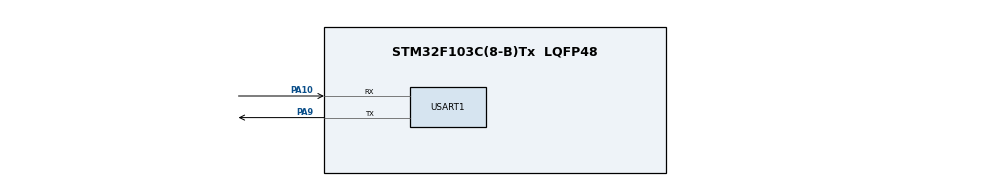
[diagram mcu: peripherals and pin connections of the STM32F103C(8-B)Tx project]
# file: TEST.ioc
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Dma.Request0=USART1_RX
Dma.Request1=USART1_TX
Dma.USART1_RX.0.Direction=DMA_PERIPH_TO_MEMORY
Dma.USART1_RX.0.Instance=DMA1_Channel5
Dma.USART1_RX.0.MemDataAlignment=DMA_MDATAALIGN_BYTE
Dma.USART1_RX.0.MemInc=DMA_MINC_ENABLE
Dma.USART1_RX.0.Mode=DMA_CIRCULAR
Dma.USART1_RX.0.PeriphDataAlignment=DMA_PDATAALIGN_BYTE
Dma.USART1_RX.0.PeriphInc=DMA_PINC_DISABLE
Dma.USART1_RX.0.Priority=DMA_PRIORITY_LOW
Dma.USART1_TX.1.Direction=DMA_MEMORY_TO_PERIPH
Dma.USART1_TX.1.Instance=DMA1_Channel4
Dma.USART1_TX.1.MemDataAlignment=DMA_MDATAALIGN_BYTE
Dma.USART1_TX.1.MemInc=DMA_MINC_ENABLE
Dma.USART1_TX.1.Mode=DMA_NORMAL
Dma.USART1_TX.1.PeriphDataAlignment=DMA_PDATAALIGN_BYTE
Dma.USART1_TX.1.PeriphInc=DMA_PINC_DISABLE
Dma.USART1_TX.1.Priority=DMA_PRIORITY_LOW
Mcu.Family=STM32F1
Mcu.Name=STM32F103C(8-B)Tx
Mcu.Package=LQFP48
NVIC.DMA1_Channel4_IRQn=true\:0\:0\:false\:false\:true\:false\:true
NVIC.DMA1_Channel5_IRQn=true\:0\:0\:false\:false\:true\:false\:true
NVIC.PriorityGroup=NVIC_PRIORITYGROUP_4
NVIC.USART1_IRQn=true\:0\:0\:false\:false\:true\:true\:true
PA10.Mode=Asynchronous
PA10.Signal=USART1_RX
PA13.Mode=Serial_Wire
PA13.Signal=SYS_JTMS-SWDIO
PA14.Mode=Serial_Wire
PA14.Signal=SYS_JTCK-SWCLK
PA9.Mode=Asynchronous
PA9.Signal=USART1_TX
PD0-OSC_IN.Mode=HSE-External-Oscillator
PD0-OSC_IN.Signal=RCC_OSC_IN
PD1-OSC_OUT.Mode=HSE-External-Oscillator
PD1-OSC_OUT.Signal=RCC_OSC_OUT
ProjectManager.HeapSize=0x200
ProjectManager.StackSize=0x400
ProjectManager.TargetToolchain=MDK-ARM V5.27
RCC.AHBFreq_Value=72000000
RCC.APB1CLKDivider=RCC_HCLK_DIV2
RCC.APB1Freq_Value=36000000
RCC.APB1TimFreq_Value=72000000
RCC.APB2Freq_Value=72000000
RCC.APB2TimFreq_Value=72000000
RCC.HCLKFreq_Value=72000000
RCC.PLLMUL=RCC_PLL_MUL9
RCC.PLLSourceVirtual=RCC_PLLSOURCE_HSE
RCC.SYSCLKFreq_VALUE=72000000
RCC.SYSCLKSource=RCC_SYSCLKSOURCE_PLLCLK
RCC.USBFreq_Value=72000000
USART1.VirtualMode=VM_ASYNC
board=custom

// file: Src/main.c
/* USER CODE BEGIN Header */
/**
  ******************************************************************************
  * @file           : main.c
  * @brief          : Main program body
  ******************************************************************************
  * @attention
  *
  * <h2><center>&copy; Copyright (c) 2021 STMicroelectronics.
  * All rights reserved.</center></h2>
  *
  * This software component is licensed by ST under BSD 3-Clause license,
  * the "License"; You may not use this file except in compliance with the
  * License. You may obtain a copy of the License at:
  *                        opensource.org/licenses/BSD-3-Clause
  *
  ******************************************************************************
  */
/* USER CODE END Header */
#include "main.h"

/* USER CODE BEGIN Includes */
#include "dma.h"

/* USER CODE END Includes */

void SystemClock_Config(void);
static void MX_GPIO_Init(void);
static void MX_DMA_Init(void);
static void MX_USART1_UART_Init(void);

int main(void)
{

  /* MCU Configuration--------------------------------------------------------*/

  /* Reset of all peripherals, Initializes the Flash interface and the Systick. */

  LL_APB2_GRP1_EnableClock(LL_APB2_GRP1_PERIPH_AFIO);
  LL_APB1_GRP1_EnableClock(LL_APB1_GRP1_PERIPH_PWR);

  NVIC_SetPriorityGrouping(NVIC_PRIORITYGROUP_4);

  /* System interrupt init*/

  /** NOJTAG: JTAG-DP Disabled and SW-DP Enabled
  */
  LL_GPIO_AF_Remap_SWJ_NOJTAG();

  /* Configure the system clock */
  SystemClock_Config();

  /* Initialize all configured peripherals */
  MX_GPIO_Init();
  MX_DMA_Init();
  MX_USART1_UART_Init();
  /* USER CODE BEGIN 2 */
  LL_Init();
  usart_init();
  usart_send_string("USART DMA example: DMA HT & TC + USART IDLE LINE interrupts\r\n");
  /* USER CODE END 2 */

  /* Infinite loop */
  while (1)
  {

  }
}

void SystemClock_Config(void)
{
  LL_FLASH_SetLatency(LL_FLASH_LATENCY_2);
  while(LL_FLASH_GetLatency()!= LL_FLASH_LATENCY_2)
  {
  }
  LL_RCC_HSE_Enable();

   /* Wait till HSE is ready */
  while(LL_RCC_HSE_IsReady() != 1)
  {

  }
  LL_RCC_PLL_ConfigDomain_SYS(LL_RCC_PLLSOURCE_HSE_DIV_1, LL_RCC_PLL_MUL_9);
  LL_RCC_PLL_Enable();

   /* Wait till PLL is ready */
  while(LL_RCC_PLL_IsReady() != 1)
  {

  }
  LL_RCC_SetAHBPrescaler(LL_RCC_SYSCLK_DIV_1);
  LL_RCC_SetAPB1Prescaler(LL_RCC_APB1_DIV_2);
  LL_RCC_SetAPB2Prescaler(LL_RCC_APB2_DIV_1);
  LL_RCC_SetSysClkSource(LL_RCC_SYS_CLKSOURCE_PLL);

   /* Wait till System clock is ready */
  while(LL_RCC_GetSysClkSource() != LL_RCC_SYS_CLKSOURCE_STATUS_PLL)
  {

  }
  LL_Init1msTick(72000000);
  LL_SetSystemCoreClock(72000000);
}

static void MX_USART1_UART_Init(void)
{

  LL_USART_InitTypeDef USART_InitStruct = {0};

  LL_GPIO_InitTypeDef GPIO_InitStruct = {0};

  /* Peripheral clock enable */
  LL_APB2_GRP1_EnableClock(LL_APB2_GRP1_PERIPH_USART1);

  LL_APB2_GRP1_EnableClock(LL_APB2_GRP1_PERIPH_GPIOA);
  /**USART1 GPIO Configuration
  PA9   ------> USART1_TX
  PA10   ------> USART1_RX
  */
  GPIO_InitStruct.Pin = LL_GPIO_PIN_9;
  GPIO_InitStruct.Mode = LL_GPIO_MODE_ALTERNATE;
  GPIO_InitStruct.Speed = LL_GPIO_SPEED_FREQ_HIGH;
  GPIO_InitStruct.OutputType = LL_GPIO_OUTPUT_PUSHPULL;
  LL_GPIO_Init(GPIOA, &GPIO_InitStruct);

  GPIO_InitStruct.Pin = LL_GPIO_PIN_10;
  GPIO_InitStruct.Mode = LL_GPIO_MODE_FLOATING;
  LL_GPIO_Init(GPIOA, &GPIO_InitStruct);

  /* USART1 DMA Init */

  /* USART1_RX Init */
  LL_DMA_SetDataTransferDirection(DMA1, LL_DMA_CHANNEL_5, LL_DMA_DIRECTION_PERIPH_TO_MEMORY);

  LL_DMA_SetChannelPriorityLevel(DMA1, LL_DMA_CHANNEL_5, LL_DMA_PRIORITY_LOW);

  LL_DMA_SetMode(DMA1, LL_DMA_CHANNEL_5, LL_DMA_MODE_CIRCULAR);

  LL_DMA_SetPeriphIncMode(DMA1, LL_DMA_CHANNEL_5, LL_DMA_PERIPH_NOINCREMENT);

  LL_DMA_SetMemoryIncMode(DMA1, LL_DMA_CHANNEL_5, LL_DMA_MEMORY_INCREMENT);

  LL_DMA_SetPeriphSize(DMA1, LL_DMA_CHANNEL_5, LL_DMA_PDATAALIGN_BYTE);

  LL_DMA_SetMemorySize(DMA1, LL_DMA_CHANNEL_5, LL_DMA_MDATAALIGN_BYTE);

  /* USART1_TX Init */
  LL_DMA_SetDataTransferDirection(DMA1, LL_DMA_CHANNEL_4, LL_DMA_DIRECTION_MEMORY_TO_PERIPH);

  LL_DMA_SetChannelPriorityLevel(DMA1, LL_DMA_CHANNEL_4, LL_DMA_PRIORITY_LOW);

  LL_DMA_SetMode(DMA1, LL_DMA_CHANNEL_4, LL_DMA_MODE_NORMAL);

  LL_DMA_SetPeriphIncMode(DMA1, LL_DMA_CHANNEL_4, LL_DMA_PERIPH_NOINCREMENT);

  LL_DMA_SetMemoryIncMode(DMA1, LL_DMA_CHANNEL_4, LL_DMA_MEMORY_INCREMENT);

  LL_DMA_SetPeriphSize(DMA1, LL_DMA_CHANNEL_4, LL_DMA_PDATAALIGN_BYTE);

  LL_DMA_SetMemorySize(DMA1, LL_DMA_CHANNEL_4, LL_DMA_MDATAALIGN_BYTE);

  /* USART1 interrupt Init */
  NVIC_SetPriority(USART1_IRQn, NVIC_EncodePriority(NVIC_GetPriorityGrouping(),0, 0));
  NVIC_EnableIRQ(USART1_IRQn);

  USART_InitStruct.BaudRate = 115200;
  USART_InitStruct.DataWidth = LL_USART_DATAWIDTH_8B;
  USART_InitStruct.StopBits = LL_USART_STOPBITS_1;
  USART_InitStruct.Parity = LL_USART_PARITY_NONE;
  USART_InitStruct.TransferDirection = LL_USART_DIRECTION_TX_RX;
  USART_InitStruct.HardwareFlowControl = LL_USART_HWCONTROL_NONE;
  USART_InitStruct.OverSampling = LL_USART_OVERSAMPLING_16;
  LL_USART_Init(USART1, &USART_InitStruct);
  LL_USART_ConfigAsyncMode(USART1);
  LL_USART_Enable(USART1);

}

static void MX_DMA_Init(void)
{

  /* Init with LL driver */
  /* DMA controller clock enable */
  LL_AHB1_GRP1_EnableClock(LL_AHB1_GRP1_PERIPH_DMA1);

  /* DMA interrupt init */
  /* DMA1_Channel4_IRQn interrupt configuration */
  NVIC_SetPriority(DMA1_Channel4_IRQn, NVIC_EncodePriority(NVIC_GetPriorityGrouping(),0, 0));
  NVIC_EnableIRQ(DMA1_Channel4_IRQn);
  /* DMA1_Channel5_IRQn interrupt configuration */
  NVIC_SetPriority(DMA1_Channel5_IRQn, NVIC_EncodePriority(NVIC_GetPriorityGrouping(),0, 0));
  NVIC_EnableIRQ(DMA1_Channel5_IRQn);

}

static void MX_GPIO_Init(void)
{

  /* GPIO Ports Clock Enable */
  LL_APB2_GRP1_EnableClock(LL_APB2_GRP1_PERIPH_GPIOD);
  LL_APB2_GRP1_EnableClock(LL_APB2_GRP1_PERIPH_GPIOA);

}

void Error_Handler(void)
{
  __disable_irq();
  while (1)
  {
  }
}

/************************ (C) COPYRIGHT STMicroelectronics *****END OF FILE****/
